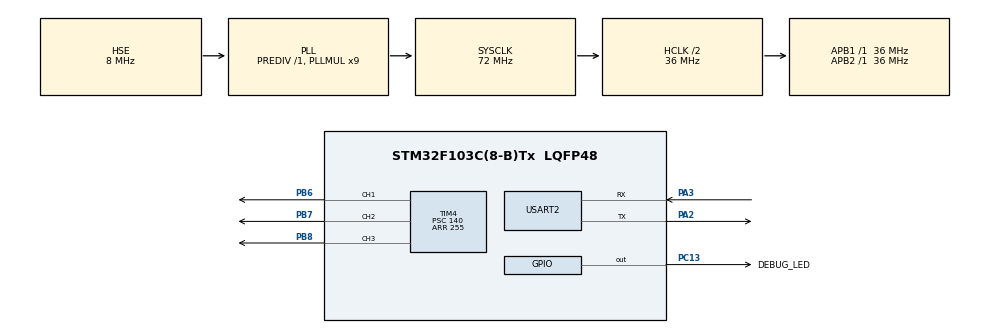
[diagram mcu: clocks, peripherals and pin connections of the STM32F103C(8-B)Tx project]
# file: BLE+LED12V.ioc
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Mcu.Family=STM32F1
Mcu.Name=STM32F103C(8-B)Tx
Mcu.Package=LQFP48
NVIC.PriorityGroup=NVIC_PRIORITYGROUP_4
NVIC.TIM1_UP_IRQn=true\:0\:0\:false\:false\:true\:true
NVIC.USART2_IRQn=true\:0\:0\:false\:false\:true\:true
PA13.Mode=Serial_Wire
PA13.Signal=SYS_JTMS-SWDIO
PA14.Mode=Serial_Wire
PA14.Signal=SYS_JTCK-SWCLK
PA2.Mode=Asynchronous
PA2.Signal=USART2_TX
PA3.Mode=Asynchronous
PA3.Signal=USART2_RX
PB6.Signal=S_TIM4_CH1
PB7.Signal=S_TIM4_CH2
PB8.Signal=S_TIM4_CH3
PC13-TAMPER-RTC.GPIO_Label=DEBUG_LED
PC13-TAMPER-RTC.Signal=GPIO_Output
PD0-OSC_IN.Mode=HSE-External-Oscillator
PD0-OSC_IN.Signal=RCC_OSC_IN
PD1-OSC_OUT.Mode=HSE-External-Oscillator
PD1-OSC_OUT.Signal=RCC_OSC_OUT
ProjectManager.HeapSize=0x200
ProjectManager.StackSize=0x400
ProjectManager.TargetToolchain=MDK-ARM V5
RCC.AHBCLKDivider=RCC_SYSCLK_DIV2
RCC.AHBFreq_Value=36000000
RCC.APB1Freq_Value=36000000
RCC.APB1TimFreq_Value=36000000
RCC.APB2Freq_Value=36000000
RCC.APB2TimFreq_Value=36000000
RCC.HCLKFreq_Value=36000000
RCC.PLLMUL=RCC_PLL_MUL9
RCC.PLLSourceVirtual=RCC_PLLSOURCE_HSE
RCC.SYSCLKFreq_VALUE=72000000
RCC.SYSCLKSource=RCC_SYSCLKSOURCE_PLLCLK
RCC.USBFreq_Value=72000000
SH.S_TIM4_CH1.0=TIM4_CH1,PWM Generation1 CH1
SH.S_TIM4_CH2.0=TIM4_CH2,PWM Generation2 CH2
SH.S_TIM4_CH3.0=TIM4_CH3,PWM Generation3 CH3
TIM1.Period=1000 - 1
TIM1.Prescaler=36 - 1
TIM1.TIM_MasterOutputTrigger=TIM_TRGO_UPDATE
TIM4.Channel-PWM\ Generation1\ CH1=TIM_CHANNEL_1
TIM4.Channel-PWM\ Generation2\ CH2=TIM_CHANNEL_2
TIM4.Channel-PWM\ Generation3\ CH3=TIM_CHANNEL_3
TIM4.Period=255
TIM4.Prescaler=140
TIM4.TIM_MasterOutputTrigger=TIM_TRGO_UPDATE
USART2.VirtualMode=VM_ASYNC
VP_TIM1_VS_ClockSourceINT.Mode=Internal
VP_TIM4_VS_ClockSourceINT.Mode=Internal
board=smart-balkony

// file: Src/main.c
/**
  ******************************************************************************
  * File Name          : main.c
  * Description        : Main program body
  ******************************************************************************
  ** This notice applies to any and all portions of this file
  * that are not between comment pairs USER CODE BEGIN and
  * USER CODE END. Other portions of this file, whether
  * inserted by the user or by software development tools
  * are owned by their respective copyright owners.
  *
  * COPYRIGHT(c) 2018 STMicroelectronics
  *
  * Redistribution and use in source and binary forms, with or without modification,
  * are permitted provided that the following conditions are met:
  *   1. Redistributions of source code must retain the above copyright notice,
  *      this list of conditions and the following disclaimer.
  *   2. Redistributions in binary form must reproduce the above copyright notice,
  *      this list of conditions and the following disclaimer in the documentation
  *      and/or other materials provided with the distribution.
  *   3. Neither the name of STMicroelectronics nor the names of its contributors
  *      may be used to endorse or promote products derived from this software
  *      without specific prior written permission.
  *
  * THIS SOFTWARE IS PROVIDED BY THE COPYRIGHT HOLDERS AND CONTRIBUTORS "AS IS"
  * AND ANY EXPRESS OR IMPLIED WARRANTIES, INCLUDING, BUT NOT LIMITED TO, THE
  * IMPLIED WARRANTIES OF MERCHANTABILITY AND FITNESS FOR A PARTICULAR PURPOSE ARE
  * DISCLAIMED. IN NO EVENT SHALL THE COPYRIGHT HOLDER OR CONTRIBUTORS BE LIABLE
  * FOR ANY DIRECT, INDIRECT, INCIDENTAL, SPECIAL, EXEMPLARY, OR CONSEQUENTIAL
  * DAMAGES (INCLUDING, BUT NOT LIMITED TO, PROCUREMENT OF SUBSTITUTE GOODS OR
  * SERVICES; LOSS OF USE, DATA, OR PROFITS; OR BUSINESS INTERRUPTION) HOWEVER
  * CAUSED AND ON ANY THEORY OF LIABILITY, WHETHER IN CONTRACT, STRICT LIABILITY,
  * OR TORT (INCLUDING NEGLIGENCE OR OTHERWISE) ARISING IN ANY WAY OUT OF THE USE
  * OF THIS SOFTWARE, EVEN IF ADVISED OF THE POSSIBILITY OF SUCH DAMAGE.
  *
  ******************************************************************************
  */

#include "main.h"
#include "stm32f1xx_hal.h"

TIM_HandleTypeDef htim1;
TIM_HandleTypeDef htim4;

UART_HandleTypeDef huart2;

/* USER CODE BEGIN PV */
/* Private variables ---------------------------------------------------------*/
uint8_t buf_rec[9] = {0};
/* USER CODE END PV */

void SystemClock_Config(void);
static void MX_GPIO_Init(void);
static void MX_USART2_UART_Init(void);
static void MX_TIM1_Init(void);
static void MX_TIM4_Init(void);

void HAL_TIM_MspPostInit(TIM_HandleTypeDef *htim);

/* USER CODE BEGIN PFP */
/* Private function prototypes -----------------------------------------------*/

/* USER CODE END PFP */

int main(void)
{

  /* MCU Configuration----------------------------------------------------------*/

  /* Reset of all peripherals, Initializes the Flash interface and the Systick. */
  HAL_Init();

  /* Configure the system clock */
  SystemClock_Config();

  /* Initialize all configured peripherals */
  MX_GPIO_Init();
  MX_USART2_UART_Init();
  MX_TIM1_Init();
  MX_TIM4_Init();

  /* USER CODE BEGIN 2 */
	HAL_Delay(100);
	HAL_TIM_PWM_Start(&htim4, TIM_CHANNEL_1);
	HAL_TIM_PWM_Start(&htim4, TIM_CHANNEL_2);
	HAL_TIM_PWM_Start(&htim4, TIM_CHANNEL_3);

	TIM4->CCR1 = 0;
	TIM4->CCR2 = 0;
	TIM4->CCR3 = 0;

  HAL_TIM_Base_Start_IT(&htim1);

	HAL_Delay(100);

	__HAL_UART_ENABLE_IT(&huart2, UART_IT_RXNE);
  __HAL_TIM_ENABLE_IT(&htim1, TIM_IT_UPDATE);
  /* USER CODE END 2 */

	HAL_Delay(100);
  /* Infinite loop */
  while (1)
  {

  }

}

/** System Clock Configuration
*/
void SystemClock_Config(void)
{

  RCC_OscInitTypeDef RCC_OscInitStruct;
  RCC_ClkInitTypeDef RCC_ClkInitStruct;

    /**Initializes the CPU, AHB and APB busses clocks
    */
  RCC_OscInitStruct.OscillatorType = RCC_OSCILLATORTYPE_HSE;
  RCC_OscInitStruct.HSEState = RCC_HSE_ON;
  RCC_OscInitStruct.HSEPredivValue = RCC_HSE_PREDIV_DIV1;
  RCC_OscInitStruct.HSIState = RCC_HSI_ON;
  RCC_OscInitStruct.PLL.PLLState = RCC_PLL_ON;
  RCC_OscInitStruct.PLL.PLLSource = RCC_PLLSOURCE_HSE;
  RCC_OscInitStruct.PLL.PLLMUL = RCC_PLL_MUL9;
  if (HAL_RCC_OscConfig(&RCC_OscInitStruct) != HAL_OK)
  {
    _Error_Handler(__FILE__, __LINE__);
  }

    /**Initializes the CPU, AHB and APB busses clocks
    */
  RCC_ClkInitStruct.ClockType = RCC_CLOCKTYPE_HCLK|RCC_CLOCKTYPE_SYSCLK
                              |RCC_CLOCKTYPE_PCLK1|RCC_CLOCKTYPE_PCLK2;
  RCC_ClkInitStruct.SYSCLKSource = RCC_SYSCLKSOURCE_PLLCLK;
  RCC_ClkInitStruct.AHBCLKDivider = RCC_SYSCLK_DIV2;
  RCC_ClkInitStruct.APB1CLKDivider = RCC_HCLK_DIV1;
  RCC_ClkInitStruct.APB2CLKDivider = RCC_HCLK_DIV1;

  if (HAL_RCC_ClockConfig(&RCC_ClkInitStruct, FLASH_LATENCY_2) != HAL_OK)
  {
    _Error_Handler(__FILE__, __LINE__);
  }

    /**Configure the Systick interrupt time
    */
  HAL_SYSTICK_Config(HAL_RCC_GetHCLKFreq()/1000);

    /**Configure the Systick
    */
  HAL_SYSTICK_CLKSourceConfig(SYSTICK_CLKSOURCE_HCLK);

  /* SysTick_IRQn interrupt configuration */
  HAL_NVIC_SetPriority(SysTick_IRQn, 0, 0);
}

/* TIM1 init function */
static void MX_TIM1_Init(void)
{

  TIM_ClockConfigTypeDef sClockSourceConfig;
  TIM_MasterConfigTypeDef sMasterConfig;

  htim1.Instance = TIM1;
  htim1.Init.Prescaler = 36000 / 16 - 1;
  htim1.Init.CounterMode = TIM_COUNTERMODE_UP;
  htim1.Init.Period = 1000 - 1;
  htim1.Init.ClockDivision = TIM_CLOCKDIVISION_DIV1;
  htim1.Init.RepetitionCounter = 0;
  htim1.Init.AutoReloadPreload = TIM_AUTORELOAD_PRELOAD_DISABLE;
  if (HAL_TIM_Base_Init(&htim1) != HAL_OK)
  {
    _Error_Handler(__FILE__, __LINE__);
  }

  sClockSourceConfig.ClockSource = TIM_CLOCKSOURCE_INTERNAL;
  if (HAL_TIM_ConfigClockSource(&htim1, &sClockSourceConfig) != HAL_OK)
  {
    _Error_Handler(__FILE__, __LINE__);
  }

  sMasterConfig.MasterOutputTrigger = TIM_TRGO_UPDATE;
  sMasterConfig.MasterSlaveMode = TIM_MASTERSLAVEMODE_DISABLE;
  if (HAL_TIMEx_MasterConfigSynchronization(&htim1, &sMasterConfig) != HAL_OK)
  {
    _Error_Handler(__FILE__, __LINE__);
  }

}

/* TIM4 init function */
static void MX_TIM4_Init(void)
{

  TIM_ClockConfigTypeDef sClockSourceConfig;
  TIM_MasterConfigTypeDef sMasterConfig;
  TIM_OC_InitTypeDef sConfigOC;

  htim4.Instance = TIM4;
  htim4.Init.Prescaler = 140 * 4 - 1;
  htim4.Init.CounterMode = TIM_COUNTERMODE_UP;
  htim4.Init.Period = 255;
  htim4.Init.ClockDivision = TIM_CLOCKDIVISION_DIV1;
  htim4.Init.AutoReloadPreload = TIM_AUTORELOAD_PRELOAD_DISABLE;
  if (HAL_TIM_Base_Init(&htim4) != HAL_OK)
  {
    _Error_Handler(__FILE__, __LINE__);
  }

  sClockSourceConfig.ClockSource = TIM_CLOCKSOURCE_INTERNAL;
  if (HAL_TIM_ConfigClockSource(&htim4, &sClockSourceConfig) != HAL_OK)
  {
    _Error_Handler(__FILE__, __LINE__);
  }

  if (HAL_TIM_PWM_Init(&htim4) != HAL_OK)
  {
    _Error_Handler(__FILE__, __LINE__);
  }

  sMasterConfig.MasterOutputTrigger = TIM_TRGO_UPDATE;
  sMasterConfig.MasterSlaveMode = TIM_MASTERSLAVEMODE_DISABLE;
  if (HAL_TIMEx_MasterConfigSynchronization(&htim4, &sMasterConfig) != HAL_OK)
  {
    _Error_Handler(__FILE__, __LINE__);
  }

  sConfigOC.OCMode = TIM_OCMODE_PWM1;
  sConfigOC.Pulse = 0;
  sConfigOC.OCPolarity = TIM_OCPOLARITY_HIGH;
  sConfigOC.OCFastMode = TIM_OCFAST_DISABLE;
  if (HAL_TIM_PWM_ConfigChannel(&htim4, &sConfigOC, TIM_CHANNEL_1) != HAL_OK)
  {
    _Error_Handler(__FILE__, __LINE__);
  }

  if (HAL_TIM_PWM_ConfigChannel(&htim4, &sConfigOC, TIM_CHANNEL_2) != HAL_OK)
  {
    _Error_Handler(__FILE__, __LINE__);
  }

  if (HAL_TIM_PWM_ConfigChannel(&htim4, &sConfigOC, TIM_CHANNEL_3) != HAL_OK)
  {
    _Error_Handler(__FILE__, __LINE__);
  }

  HAL_TIM_MspPostInit(&htim4);

}

/* USART2 init function */
static void MX_USART2_UART_Init(void)
{

  huart2.Instance = USART2;
  huart2.Init.BaudRate = 115200;
  huart2.Init.WordLength = UART_WORDLENGTH_8B;
  huart2.Init.StopBits = UART_STOPBITS_1;
  huart2.Init.Parity = UART_PARITY_NONE;
  huart2.Init.Mode = UART_MODE_TX_RX;
  huart2.Init.HwFlowCtl = UART_HWCONTROL_NONE;
  huart2.Init.OverSampling = UART_OVERSAMPLING_16;
  if (HAL_UART_Init(&huart2) != HAL_OK)
  {
    _Error_Handler(__FILE__, __LINE__);
  }

}

/** Configure pins as
        * Analog
        * Input
        * Output
        * EVENT_OUT
        * EXTI
*/
static void MX_GPIO_Init(void)
{

  GPIO_InitTypeDef GPIO_InitStruct;

  /* GPIO Ports Clock Enable */
  __HAL_RCC_GPIOC_CLK_ENABLE();
  __HAL_RCC_GPIOD_CLK_ENABLE();
  __HAL_RCC_GPIOA_CLK_ENABLE();
  __HAL_RCC_GPIOB_CLK_ENABLE();

  /*Configure GPIO pin Output Level */
  HAL_GPIO_WritePin(DEBUG_LED_GPIO_Port, DEBUG_LED_Pin, GPIO_PIN_RESET);

  /*Configure GPIO pin : DEBUG_LED_Pin */
  GPIO_InitStruct.Pin = DEBUG_LED_Pin;
  GPIO_InitStruct.Mode = GPIO_MODE_OUTPUT_PP;
  GPIO_InitStruct.Speed = GPIO_SPEED_FREQ_LOW;
  HAL_GPIO_Init(DEBUG_LED_GPIO_Port, &GPIO_InitStruct);

}

void _Error_Handler(char * file, int line)
{
  while(1)
  {
  }
}

/************************ (C) COPYRIGHT STMicroelectronics *****END OF FILE****/
